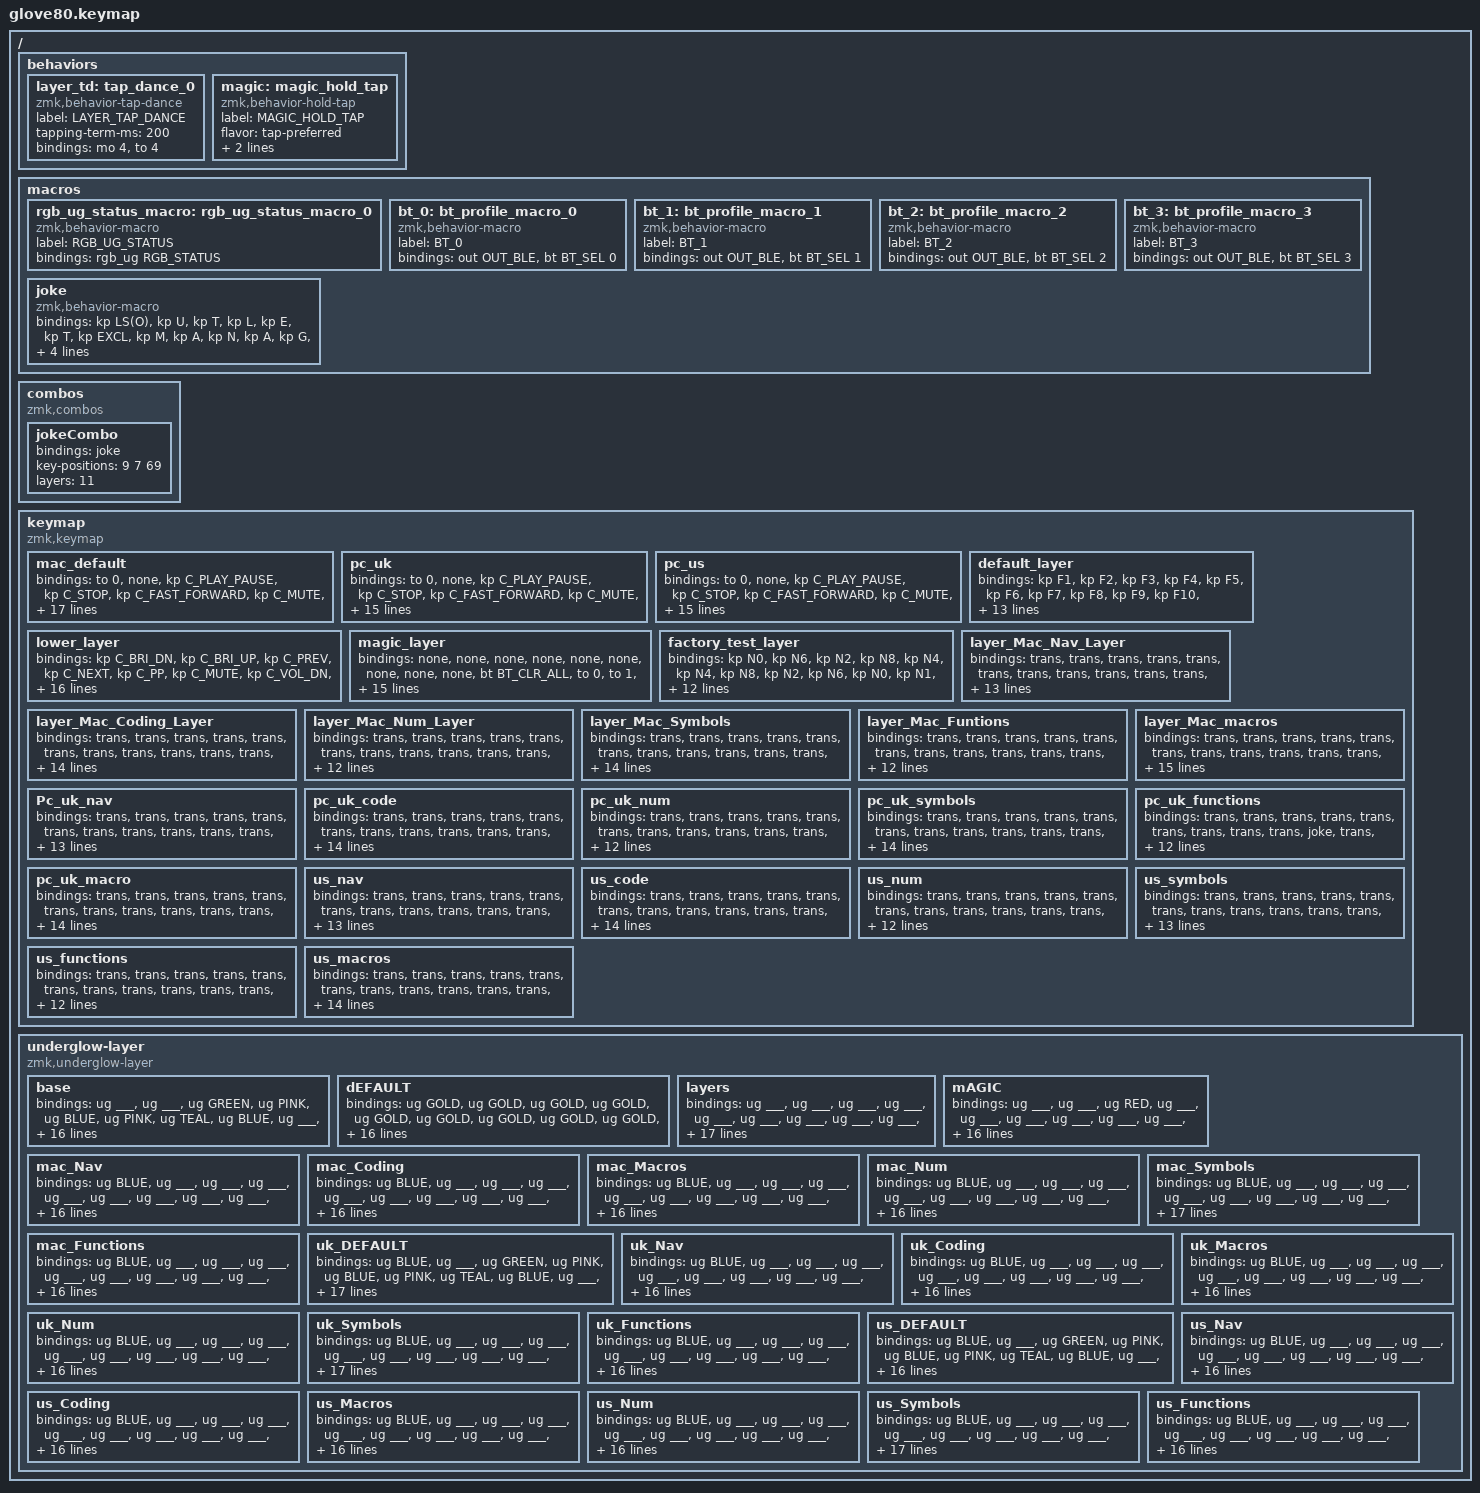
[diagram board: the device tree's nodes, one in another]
/*
 * Copyright (c) 2020 The ZMK Contributors
 *
 * SPDX-License-Identifier: MIT
 */

#include <dt-bindings/zmk/rgb_colors.h>
#include <behaviors.dtsi>
#include <dt-bindings/zmk/bt.h>
#include <dt-bindings/zmk/keys.h>
#include <dt-bindings/zmk/outputs.h>
#include <dt-bindings/zmk/rgb.h>

#define HYPER LC(LS(LG(LALT)))

// layers

#define MAC_DEFAULT 0
#define DEFAULT 3
#define UK_DEFAULT 1
#define US_DEFAULT 2
#define LOWER 4
#define MAGIC 5
#define FACTORY_TEST 6
#define MAC_Nav 7
#define MAC_Coding 8
#define MAC_Num 9
#define MAC_Symbols 10
#define MAC_Functions 11
#define MAC_Macros 12
#define UK_Nav 13
#define UK_Coding 14
#define UK_Num 15
#define UK_Symbols 16
#define UK_Functions 17
#define UK_Macros 18
#define US_Nav 19
#define US_Coding 20
#define US_Num 21
#define US_Symbols 22
#define US_Functions 23
#define US_Macros 24

/ {
    behaviors {
        // For the "layer" key, it'd nice to be able to use it as either a shift or a toggle.
        // Configure it as a tap dance, so the first tap (or hold) is a &mo and the second tap is a &to

        layer_td: tap_dance_0 {
            compatible = "zmk,behavior-tap-dance";
            label = "LAYER_TAP_DANCE";
            #binding-cells = <0>;
            tapping-term-ms = <200>;
            bindings = <&mo 4>, <&to 4>;
        };

        magic: magic_hold_tap {
            compatible = "zmk,behavior-hold-tap";
            label = "MAGIC_HOLD_TAP";
            #binding-cells = <2>;
            flavor = "tap-preferred";
            tapping-term-ms = <200>;
            bindings = <&mo>, <&rgb_ug_status_macro>;
        };
    };

    macros {
        rgb_ug_status_macro: rgb_ug_status_macro_0 {
            label = "RGB_UG_STATUS";
            compatible = "zmk,behavior-macro";
            #binding-cells = <0>;
            bindings = <&rgb_ug RGB_STATUS>;
        };

        bt_0: bt_profile_macro_0 {
            label = "BT_0";
            compatible = "zmk,behavior-macro";
            #binding-cells = <0>;
            bindings = <&out OUT_BLE &bt BT_SEL 0>;
        };

        bt_1: bt_profile_macro_1 {
            label = "BT_1";
            compatible = "zmk,behavior-macro";
            #binding-cells = <0>;
            bindings = <&out OUT_BLE &bt BT_SEL 1>;
        };

        bt_2: bt_profile_macro_2 {
            label = "BT_2";
            compatible = "zmk,behavior-macro";
            #binding-cells = <0>;
            bindings = <&out OUT_BLE &bt BT_SEL 2>;
        };

        bt_3: bt_profile_macro_3 {
            label = "BT_3";
            compatible = "zmk,behavior-macro";
            #binding-cells = <0>;
            bindings = <&out OUT_BLE &bt BT_SEL 3>;
        };

        joke: joke {
            compatible = "zmk,behavior-macro";
            #binding-cells = <0>;
            bindings = <&kp LS(O) &kp U &kp T &kp L &kp E &kp T &kp EXCL &kp M &kp A &kp N &kp A &kp G &kp I &kp N &kp G &kp EXCL &kp W &kp I &kp Z &kp A &kp R &kp D &kp N2 &kp M &kp A &kp K &kp I &kp N &kp G>;
            label = "JOKE";
        };
    };

    combos {
        compatible = "zmk,combos";

        jokeCombo {
            bindings = <&joke>;
            key-positions = <9 7 69>;
            layers = <11>;
        };
    };

    keymap {
        compatible = "zmk,keymap";

        mac_default {
            bindings = <
&to 0       &none               &kp C_PLAY_PAUSE  &kp C_STOP      &kp C_FAST_FORWARD                                                                                                  &kp C_MUTE         &kp C_VOLUME_DOWN  &kp C_VOL_UP     &rgb_ug RGB_ON       &rgb_ug RGB_OFF
&none       &none               &none             &none           &none               &none                                                                                    &none  &none              &none              &none            &none                &none
&none       &kp Q               &kp W             &kp F           &kp P               &kp B                                                                                    &kp J  &kp L              &kp U              &kp Y            &kp LS(SLASH)        &none
&none       &mt LEFT_CONTROL A  &mt LEFT_ALT R    &mt LEFT_WIN S  &mt LEFT_SHIFT T    &kp G                                                                                    &kp M  &mt RIGHT_SHIFT N  &mt RIGHT_WIN E    &mt RIGHT_ALT I  &mt RIGHT_CONTROL O  &none
&none       &kp Z               &kp X             &kp C           &kp D               &kp V  &none        &none       &none       &none          &none        &none            &kp K  &kp H              &kp COMMA          &kp PERIOD       &kp LS(FSLH)         &none
&magic 5 0  &none               &none             &none           &none                      &lt 9 SPACE  &lt 10 TAB  &lt 11 ESC  &lt 12 DELETE  &lt 8 ENTER  &lt 7 BACKSPACE         &none              &none              &none            &none                &magic 5 0
            >;
        };

        pc_uk {
            bindings = <
&to 0       &none           &kp C_PLAY_PAUSE  &kp C_STOP   &kp C_FAST_FORWARD                                                                                                     &kp C_MUTE         &kp C_VOLUME_DOWN  &kp C_VOL_UP     &none              &none
&none       &none           &none             &none        &none               &none                                                                                       &none  &none              &none              &none            &none              &none
&none       &kp Q           &kp W             &kp F        &kp P               &kp B                                                                                       &kp J  &kp L              &kp U              &kp Y            &kp APOS           &none
&none       &mt LEFT_WIN A  &mt LEFT_ALT R    &mt LCTRL S  &mt LEFT_SHIFT T    &kp G                                                                                       &kp M  &mt RIGHT_SHIFT N  &mt RCTRL E        &mt RIGHT_ALT I  &mt RIGHT_WIN O    &none
&none       &kp Z           &kp X             &kp C        &kp D               &kp V  &none         &none       &none       &none          &none         &none             &kp K  &kp H              &kp COMMA          &kp DOT          &kp RA(BACKSLASH)  &none
&magic 5 0  &none           &none             &none        &none                      &lt 15 SPACE  &lt 16 TAB  &lt 17 ESC  &lt 18 DELETE  &lt 14 ENTER  &lt 13 BACKSPACE         &none              &none              &none            &none              &magic 5 0
            >;
        };

        pc_us {
            bindings = <
&to 0       &none           &kp C_PLAY_PAUSE  &kp C_STOP   &kp C_FAST_FORWARD                                                                                                     &kp C_MUTE         &kp C_VOLUME_DOWN  &kp C_VOL_UP     &none            &none
&none       &none           &none             &none        &none               &none                                                                                       &none  &none              &none              &none            &none            &none
&none       &kp Q           &kp W             &kp F        &kp P               &kp B                                                                                       &kp J  &kp L              &kp U              &kp Y            &kp UNDER        &none
&none       &mt LEFT_WIN A  &mt LEFT_ALT R    &mt LCTRL S  &mt LEFT_SHIFT T    &kp G                                                                                       &kp M  &mt RIGHT_SHIFT N  &mt RCTRL E        &mt RIGHT_ALT I  &mt RIGHT_WIN O  &none
&none       &kp Z           &kp X             &kp C        &kp D               &kp V  &none         &none       &none       &none          &none         &none             &kp K  &kp H              &kp COMMA          &kp DOT          &kp LS(FSLH)     &none
&magic 5 0  &none           &none             &none        &none                      &lt 21 SPACE  &lt 22 TAB  &lt 23 ESC  &lt 24 DELETE  &lt 20 ENTER  &lt 19 BACKSPACE         &none              &none              &none            &none            &magic 5 0
            >;
        };

        default_layer {
            // ---------------------------------------------------------------------------------------------------------------------------------
            // |  F1   |  F2 |  F3 |  F4  |  F5  |                                                               |  F6   |  F7   |  F8  |   F9  |  F10 |
            // |  =    |  1  |  2  |  3   |  4   |  5   |                                                 |  6   |   7   |   8   |  9   |   0   |   -  |
            // |  TAB  |  Q  |  W  |  E   |  R   |  T   |                                                 |  Y   |   U   |   I   |  O   |   P   |   \  |
            // |  ESC  |  A  |  S  |  D   |  F   |  G   |                                                 |  H   |   J   |   K   |  L   |   ;   |   '  |
            // |   `   |  Z  |  X  |  C   |  V   |  B   | LSHFT | LCTRL | LOWER | | LGUI  | RCTRL | RSHFT |  N   |   M   |   ,   |  .   |   /   | PGUP |
            // | MAGIC | HOME| END | LEFT | RIGHT|      | BSPC  | DEL   | LALT  | | RALT  | RET   | SPACE |      |  UP   | DOWN  |  [   |   ]   | PGDN |

            bindings = <
&kp F1      &kp F2    &kp F3   &kp F4    &kp F5                                                                                      &kp F6  &kp F7     &kp F8    &kp F9    &kp F10
&kp EQUAL   &kp N1    &kp N2   &kp N3    &kp N4     &kp N5                                                                   &kp N6  &kp N7  &kp N8     &kp N9    &kp N0    &kp MINUS
&kp TAB     &kp Q     &kp W    &kp E     &kp R      &kp T                                                                    &kp Y   &kp U   &kp I      &kp O     &kp P     &kp BSLH
&kp ESC     &kp A     &kp S    &kp D     &kp F      &kp G                                                                    &kp H   &kp J   &kp K      &kp L     &kp SEMI  &kp SQT
&kp GRAVE   &kp Z     &kp X    &kp C     &kp V      &kp B   &kp LSHFT  &kp LCTRL  &layer_td  &kp LGUI  &kp RCTRL  &kp RSHFT  &kp N   &kp M   &kp COMMA  &kp DOT   &kp FSLH  &kp PG_UP
&magic 5 0  &kp HOME  &kp END  &kp LEFT  &kp RIGHT          &kp BSPC   &kp DEL    &kp LALT   &kp RALT  &kp RET    &kp SPACE          &kp UP  &kp DOWN   &kp LBKT  &kp RBKT  &kp PG_DN
            >;
        };

        lower_layer {
            bindings = <
&kp C_BRI_DN  &kp C_BRI_UP  &kp C_PREV  &kp C_NEXT  &kp C_PP                                                                         &kp C_MUTE  &kp C_VOL_DN  &kp C_VOL_UP   &none            &kp PAUSE_BREAK
&trans        &none         &none       &none       &none      &kp HOME                                                   &kp LPAR   &kp KP_NUM  &kp KP_EQUAL  &kp KP_DIVIDE  &kp KP_MULTIPLY  &kp PSCRN
&trans        &none         &none       &kp UP      &none      &kp END                                                    &kp RPAR   &kp KP_N7   &kp KP_N8     &kp KP_N9      &kp KP_MINUS     &kp SLCK
&trans        &none         &kp LEFT    &kp DOWN    &kp RIGHT  &kp PG_UP                                                  &kp PRCNT  &kp KP_N4   &kp KP_N5     &kp KP_N6      &kp KP_PLUS      &none
&trans        &kp K_CMENU   &none       &kp F11     &kp F12    &kp PG_DN  &trans  &trans  &to 3   &trans  &trans  &trans  &kp COMMA  &kp KP_N1   &kp KP_N2     &kp KP_N3      &kp KP_ENTER     &trans
&trans        &kp CAPS      &kp INS     &kp F11     &kp F12               &trans  &trans  &trans  &trans  &trans  &trans             &kp KP_N0   &kp KP_N0     &kp KP_DOT     &kp KP_ENTER     &trans
            >;
        };

        magic_layer {
            bindings = <
&none        &none            &none            &none            &none                                                                                     &none         &none         &none         &none  &bt BT_CLR_ALL
&to 0        &to 1            &to 2            &to 3            &bt_3            &none                                                             &none  &none         &none         &none         &none  &bt BT_CLR
&none        &rgb_ug RGB_SPI  &rgb_ug RGB_SAI  &rgb_ug RGB_HUI  &rgb_ug RGB_BRI  &rgb_ug RGB_TOG                                                   &none  &none         &none         &none         &none  &none
&bootloader  &rgb_ug RGB_SPD  &rgb_ug RGB_SAD  &rgb_ug RGB_HUD  &rgb_ug RGB_BRD  &rgb_ug RGB_EFF                                                   &none  &bt BT_SEL 3  &bt BT_SEL 4  &none         &none  &bootloader
&sys_reset   &none            &none            &none            &none            &none            &bt_2  &bt_3  &none         &none  &none  &none  &none  &bt BT_SEL 0  &bt BT_SEL 1  &bt BT_SEL 2  &none  &sys_reset
&none        &none            &none            &none            &none                             &bt_0  &bt_1  &out OUT_USB  &none  &none  &none         &none         &none         &none         &none  &none
            >;
        };

        factory_test_layer {
            bindings = <
&kp N0  &kp N6  &kp N2  &kp N8  &kp N4                                                                  &kp N4  &kp N8  &kp N2  &kp N6  &kp N0
&kp N1  &kp N7  &kp N3  &kp N9  &kp N5  &kp N0                                                  &kp N0  &kp N5  &kp N9  &kp N3  &kp N7  &kp N1
&kp N2  &kp N8  &kp N4  &kp N0  &kp N6  &kp N1                                                  &kp N1  &kp N6  &kp N0  &kp N4  &kp N8  &kp N2
&kp N3  &kp N9  &kp N5  &kp N1  &kp N7  &kp N2                                                  &kp N2  &kp N7  &kp N1  &kp N5  &kp N9  &kp N3
&kp N4  &kp N0  &kp N6  &kp N2  &kp N8  &kp N3  &kp N4  &kp N5  &kp N6  &kp N6  &kp N5  &kp N4  &kp N3  &kp N8  &kp N2  &kp N6  &kp N0  &kp N4
&kp N5  &kp N1  &kp N7  &kp N3  &kp N9          &kp N7  &kp N8  &kp N9  &kp N9  &kp N8  &kp N7          &kp N9  &kp N3  &kp N7  &kp N1  &kp N5
            >;
        };

        layer_Mac_Nav_Layer {
            bindings = <
&trans  &trans     &trans     &trans     &trans                                                                            &trans  &trans  &trans  &trans  &trans
&trans  &trans     &trans     &trans     &trans     &trans                                                         &trans  &trans  &trans  &trans  &trans  &trans
&trans  &kp PG_UP  &kp HOME   &kp UP     &kp END    &kp PAGE_UP                                                    &trans  &trans  &trans  &trans  &trans  &trans
&trans  &kp F20    &kp LEFT   &kp DOWN   &kp RIGHT  &kp PAGE_DOWN                                                  &trans  &trans  &trans  &trans  &trans  &trans
&trans  &kp LG(Z)  &kp LG(X)  &kp LG(C)  &kp LG(V)  &kp LG(V)      &trans  &trans  &trans  &trans  &trans  &trans  &trans  &trans  &trans  &trans  &trans  &trans
&trans  &trans     &trans     &trans     &trans                    &trans  &trans  &trans  &trans  &trans  &trans          &trans  &trans  &trans  &trans  &trans
            >;
        };

        layer_Mac_Coding_Layer {
            bindings = <
&trans  &trans    &trans    &trans             &trans                                                                                           &trans  &trans  &trans  &trans  &trans
&trans  &trans    &trans    &trans             &trans                 &trans                                                            &trans  &trans  &trans  &trans  &trans  &trans
&trans  &kp AT    &kp SQT   &kp DOUBLE_QUOTES  &kp SEMI               &kp COLON                                                         &trans  &trans  &trans  &trans  &trans  &trans
&trans  &kp FSLH  &kp LBKT  &kp LEFT_BRACE     &kp LEFT_PARENTHESIS   &kp LESS_THAN                                                     &trans  &trans  &trans  &trans  &trans  &trans
&trans  &kp BSLH  &kp RBKT  &kp RIGHT_BRACE    &kp RIGHT_PARENTHESIS  &kp GREATER_THAN  &trans  &trans  &trans  &trans  &trans  &trans  &trans  &trans  &trans  &trans  &trans  &trans
&trans  &trans    &trans    &trans             &trans                                   &trans  &trans  &trans  &trans  &trans  &trans          &trans  &trans  &trans  &trans  &trans
            >;
        };

        layer_Mac_Num_Layer {
            bindings = <
&trans  &trans  &trans  &trans  &trans                                                                               &trans  &trans  &trans  &trans     &trans
&trans  &trans  &trans  &trans  &trans  &trans                                                            &trans     &trans  &trans  &trans  &trans     &trans
&trans  &trans  &trans  &trans  &trans  &trans                                                            &kp PLUS   &kp N7  &kp N8  &kp N9  &kp STAR   &trans
&trans  &trans  &trans  &trans  &trans  &trans                                                            &kp MINUS  &kp N4  &kp N5  &kp N6  &kp FSLH   &trans
&trans  &trans  &trans  &trans  &trans  &trans  &trans  &trans  &trans  &trans         &trans     &trans  &kp DOT    &kp N1  &kp N2  &kp N3  &kp EQUAL  &trans
&trans  &trans  &trans  &trans  &trans          &trans  &trans  &trans  &kp BACKSPACE  &kp ENTER  &kp N0             &trans  &trans  &trans  &trans     &trans
            >;
        };

        layer_Mac_Symbols {
            bindings = <
&trans  &trans  &trans  &trans  &trans                                                                            &trans      &trans       &trans            &trans         &trans
&trans  &trans  &trans  &trans  &trans  &trans                                                         &trans     &trans      &trans       &trans            &trans         &trans
&trans  &trans  &trans  &trans  &trans  &trans                                                         &kp GRAVE  &kp AMPS    &kp ASTRK    &kp HASH          &kp LS(MINUS)  &trans
&trans  &trans  &trans  &trans  &trans  &trans                                                         &kp COLON  &kp DOLLAR  &kp PERCENT  &kp CARET         &kp PLUS       &trans
&trans  &trans  &trans  &trans  &trans  &trans  &trans  &trans  &trans  &trans  &trans  &trans         &kp TILDE  &kp EXCL    &kp AT       &kp RA(NUMBER_3)  &kp PIPE       &trans
&trans  &trans  &trans  &trans  &trans          &trans  &trans  &trans  &trans  &trans  &kp BACKSPACE             &trans      &trans       &trans            &trans         &trans
            >;
        };

        layer_Mac_Funtions {
            bindings = <
&trans  &trans  &trans  &trans  &trans                                                                  &trans  &trans  &trans  &trans   &trans
&trans  &trans  &trans  &trans  &trans  &trans                                                  &trans  &trans  &trans  &trans  &trans   &trans
&trans  &trans  &trans  &trans  &trans  &trans                                                  &none   &kp F7  &kp F8  &kp F9  &kp F12  &trans
&trans  &trans  &trans  &trans  &trans  &trans                                                  &none   &kp F4  &kp F5  &kp F6  &kp F11  &trans
&trans  &trans  &trans  &trans  &trans  &trans  &trans  &trans  &trans  &trans  &trans  &trans  &none   &kp F1  &kp F2  &kp F3  &kp F10  &trans
&trans  &trans  &trans  &trans  &trans          &trans  &trans  &trans  &trans  &trans  &trans          &trans  &trans  &trans  &trans   &trans
            >;
        };

        layer_Mac_macros {
            bindings = <
&trans  &trans                &trans                  &trans             &trans                                                                                     &trans  &trans  &trans  &trans  &trans
&trans  &trans                &trans                  &trans             &trans                     &trans                                                  &trans  &trans  &trans  &trans  &trans  &trans
&trans  &kp LC(LS(O))         &kp LA(LC(LEFT_ARROW))  &kp LA(LC(RET))    &kp LA(LC(RIGHT))          &trans                                                  &trans  &trans  &trans  &trans  &trans  &trans
&trans  &kp LC(LS(C))         &kp LG(SPACE)           &kp LG(LA(C))      &kp LS(LA(LC(LG(SPACE))))  &trans                                                  &trans  &trans  &trans  &trans  &trans  &trans
&trans  &kp LA(SINGLE_QUOTE)  &kp LC(PERIOD)          &kp LA(BACKSLASH)  &kp LG(T)                  &trans  &trans  &trans  &trans  &trans  &trans  &trans  &trans  &trans  &trans  &trans  &trans  &trans
&trans  &trans                &trans                  &trans             &trans                             &trans  &trans  &trans  &trans  &trans  &trans          &trans  &trans  &trans  &trans  &trans
            >;
        };

        Pc_uk_nav {
            bindings = <
&trans  &trans     &trans     &trans     &trans                                                                            &trans  &trans  &trans  &trans  &trans
&trans  &trans     &trans     &trans     &trans     &trans                                                         &trans  &trans  &trans  &trans  &trans  &trans
&trans  &kp PG_UP  &kp HOME   &kp UP     &kp END    &kp PAGE_UP                                                    &trans  &trans  &trans  &trans  &trans  &trans
&trans  &kp PG_DN  &kp LEFT   &kp DOWN   &kp RIGHT  &kp PAGE_DOWN                                                  &trans  &trans  &trans  &trans  &trans  &trans
&trans  &kp LC(Z)  &kp LC(X)  &kp LC(C)  &kp LC(V)  &kp LC(V)      &trans  &trans  &trans  &trans  &trans  &trans  &trans  &trans  &trans  &trans  &trans  &trans
&trans  &trans     &trans     &trans     &trans                    &trans  &trans  &trans  &trans  &trans  &trans          &trans  &trans  &trans  &trans  &trans
            >;
        };

        pc_uk_code {
            bindings = <
&trans  &trans             &trans    &trans           &trans                                                                                           &trans  &trans  &trans  &trans  &trans
&trans  &trans             &trans    &trans           &trans                 &trans                                                            &trans  &trans  &trans  &trans  &trans  &trans
&trans  &kp DOUBLE_QUOTES  &kp SQT   &kp AT           &kp SEMI               &kp COLON                                                         &trans  &trans  &trans  &trans  &trans  &trans
&trans  &kp FSLH           &kp LBKT  &kp LEFT_BRACE   &kp LEFT_PARENTHESIS   &kp LESS_THAN                                                     &trans  &trans  &trans  &trans  &trans  &trans
&trans  &kp BSLH           &kp RBKT  &kp RIGHT_BRACE  &kp RIGHT_PARENTHESIS  &kp GREATER_THAN  &trans  &trans  &trans  &trans  &trans  &trans  &trans  &trans  &trans  &trans  &trans  &trans
&trans  &trans             &trans    &trans           &trans                                   &trans  &trans  &trans  &trans  &trans  &trans          &trans  &trans  &trans  &trans  &trans
            >;
        };

        pc_uk_num {
            bindings = <
&trans  &trans  &trans  &trans  &trans                                                                               &trans  &trans  &trans  &trans     &trans
&trans  &trans  &trans  &trans  &trans  &trans                                                            &trans     &trans  &trans  &trans  &trans     &trans
&trans  &trans  &trans  &trans  &trans  &trans                                                            &kp PLUS   &kp N7  &kp N8  &kp N9  &kp STAR   &trans
&trans  &trans  &trans  &trans  &trans  &trans                                                            &kp MINUS  &kp N4  &kp N5  &kp N6  &kp FSLH   &trans
&trans  &trans  &trans  &trans  &trans  &trans  &trans  &trans  &trans  &trans         &trans     &trans  &kp DOT    &kp N1  &kp N2  &kp N3  &kp EQUAL  &trans
&trans  &trans  &trans  &trans  &trans          &trans  &trans  &trans  &kp BACKSPACE  &kp ENTER  &kp N0             &trans  &trans  &trans  &trans     &trans
            >;
        };

        pc_uk_symbols {
            bindings = <
&trans  &trans  &trans  &trans  &trans                                                                            &trans      &trans             &trans         &trans             &trans
&trans  &trans  &trans  &trans  &trans  &trans                                                         &trans     &trans      &trans             &trans         &trans             &trans
&trans  &trans  &trans  &trans  &trans  &trans                                                         &kp GRAVE  &kp AMPS    &kp ASTRK          &kp HASH       &kp UNDER          &trans
&trans  &trans  &trans  &trans  &trans  &trans                                                         &kp TILDE  &kp DOLLAR  &kp PERCENT        &kp CARET      &kp PLUS           &trans
&trans  &trans  &trans  &trans  &trans  &trans  &trans  &trans  &trans  &trans  &trans  &trans         &kp PIPE   &kp EXCL    &kp DOUBLE_QUOTES  &kp BACKSLASH  &kp LS(BACKSLASH)  &trans
&trans  &trans  &trans  &trans  &trans          &trans  &trans  &trans  &trans  &trans  &kp BACKSPACE             &trans      &trans             &trans         &trans             &trans
            >;
        };

        pc_uk_functions {
            bindings = <
&trans  &trans  &trans  &trans  &trans                                                                  &trans  &trans  &trans  &trans   &joke
&trans  &trans  &trans  &trans  &trans  &trans                                                  &trans  &trans  &trans  &trans  &trans   &trans
&trans  &trans  &trans  &trans  &trans  &trans                                                  &none   &kp F7  &kp F8  &kp F9  &kp F12  &trans
&trans  &trans  &trans  &trans  &trans  &trans                                                  &none   &kp F4  &kp F5  &kp F6  &kp F11  &trans
&trans  &trans  &trans  &trans  &trans  &trans  &trans  &trans  &trans  &trans  &trans  &trans  &none   &kp F1  &kp F2  &kp F3  &kp F10  &trans
&trans  &trans  &trans  &trans  &trans          &trans  &trans  &trans  &trans  &trans  &trans          &trans  &trans  &trans  &trans   &trans
            >;
        };

        pc_uk_macro {
            bindings = <
&trans  &trans                &trans          &trans             &trans                                                                                 &trans  &trans  &trans  &trans  &trans
&trans  &trans                &trans          &trans             &trans                 &trans                                                  &trans  &trans  &trans  &trans  &trans  &trans
&trans  &none                 &trans          &trans             &trans                 &trans                                                  &trans  &trans  &trans  &trans  &trans  &trans
&trans  &kp PRINTSCREEN       &kp LG(SPACE)   &kp LA(LC(LS(C)))  &kp LS(LA(LC(SPACE)))  &trans                                                  &trans  &trans  &trans  &trans  &trans  &trans
&trans  &kp LA(SINGLE_QUOTE)  &kp LC(PERIOD)  &kp LA(BACKSLASH)  &kp LG(T)              &trans  &trans  &trans  &trans  &trans  &trans  &trans  &trans  &trans  &trans  &trans  &trans  &trans
&trans  &trans                &trans          &trans             &trans                         &trans  &trans  &trans  &trans  &trans  &trans          &trans  &trans  &trans  &trans  &trans
            >;
        };

        us_nav {
            bindings = <
&trans  &trans     &trans     &trans     &trans                                                                            &trans  &trans  &trans  &trans  &trans
&trans  &trans     &trans     &trans     &trans     &trans                                                         &trans  &trans  &trans  &trans  &trans  &trans
&trans  &kp PG_UP  &kp HOME   &kp UP     &kp END    &kp PAGE_UP                                                    &trans  &trans  &trans  &trans  &trans  &trans
&trans  &kp PG_DN  &kp LEFT   &kp DOWN   &kp RIGHT  &kp PAGE_DOWN                                                  &trans  &trans  &trans  &trans  &trans  &trans
&trans  &kp LC(Z)  &kp LC(X)  &kp LC(C)  &kp LC(V)  &kp LC(V)      &trans  &trans  &trans  &trans  &trans  &trans  &trans  &trans  &trans  &trans  &trans  &trans
&trans  &trans     &trans     &trans     &trans                    &trans  &trans  &trans  &trans  &trans  &trans          &trans  &trans  &trans  &trans  &trans
            >;
        };

        us_code {
            bindings = <
&trans  &trans    &trans    &trans             &trans                                                                                           &trans  &trans  &trans  &trans  &trans
&trans  &trans    &trans    &trans             &trans                 &trans                                                            &trans  &trans  &trans  &trans  &trans  &trans
&trans  &kp AT    &kp SQT   &kp DOUBLE_QUOTES  &kp SEMI               &kp COLON                                                         &trans  &trans  &trans  &trans  &trans  &trans
&trans  &kp FSLH  &kp LBKT  &kp LEFT_BRACE     &kp LEFT_PARENTHESIS   &kp LESS_THAN                                                     &trans  &trans  &trans  &trans  &trans  &trans
&trans  &kp BSLH  &kp RBKT  &kp RIGHT_BRACE    &kp RIGHT_PARENTHESIS  &kp GREATER_THAN  &trans  &trans  &trans  &trans  &trans  &trans  &trans  &trans  &trans  &trans  &trans  &trans
&trans  &trans    &trans    &trans             &trans                                   &trans  &trans  &trans  &trans  &trans  &trans          &trans  &trans  &trans  &trans  &trans
            >;
        };

        us_num {
            bindings = <
&trans  &trans  &trans  &trans  &trans                                                                               &trans  &trans  &trans  &trans     &trans
&trans  &trans  &trans  &trans  &trans  &trans                                                            &trans     &trans  &trans  &trans  &trans     &trans
&trans  &trans  &trans  &trans  &trans  &trans                                                            &kp PLUS   &kp N7  &kp N8  &kp N9  &kp STAR   &trans
&trans  &trans  &trans  &trans  &trans  &trans                                                            &kp MINUS  &kp N4  &kp N5  &kp N6  &kp FSLH   &trans
&trans  &trans  &trans  &trans  &trans  &trans  &trans  &trans  &trans  &trans         &trans     &trans  &kp DOT    &kp N1  &kp N2  &kp N3  &kp EQUAL  &trans
&trans  &trans  &trans  &trans  &trans          &trans  &trans  &trans  &kp BACKSPACE  &kp ENTER  &kp N0             &trans  &trans  &trans  &trans     &trans
            >;
        };

        us_symbols {
            bindings = <
&trans  &trans  &trans  &trans  &trans                                                                     &trans      &trans       &trans     &trans     &trans
&trans  &trans  &trans  &trans  &trans  &trans                                                  &trans     &trans      &trans       &trans     &trans     &trans
&trans  &trans  &trans  &trans  &trans  &trans                                                  &kp GRAVE  &kp AMPS    &kp ASTRK    &kp HASH   &kp UNDER  &trans
&trans  &trans  &trans  &trans  &trans  &trans                                                  &kp COLON  &kp DOLLAR  &kp PERCENT  &kp CARET  &kp PLUS   &trans
&trans  &trans  &trans  &trans  &trans  &trans  &trans  &trans  &trans  &trans  &trans  &trans  &kp TILDE  &kp EXCL    &kp AT       &kp HASH   &kp PIPE   &trans
&trans  &trans  &trans  &trans  &trans          &trans  &trans  &trans  &trans  &trans  &trans             &trans      &trans       &trans     &trans     &trans
            >;
        };

        us_functions {
            bindings = <
&trans  &trans  &trans  &trans  &trans                                                                  &trans  &trans  &trans  &trans   &trans
&trans  &trans  &trans  &trans  &trans  &trans                                                  &trans  &trans  &trans  &trans  &trans   &trans
&trans  &trans  &trans  &trans  &trans  &trans                                                  &none   &kp F7  &kp F8  &kp F9  &kp F12  &trans
&trans  &trans  &trans  &trans  &trans  &trans                                                  &none   &kp F4  &kp F5  &kp F6  &kp F11  &trans
&trans  &trans  &trans  &trans  &trans  &trans  &trans  &trans  &trans  &trans  &trans  &trans  &none   &kp F1  &kp F2  &kp F3  &kp F10  &trans
&trans  &trans  &trans  &trans  &trans          &trans  &trans  &trans  &trans  &trans  &trans          &trans  &trans  &trans  &trans   &trans
            >;
        };

        us_macros {
            bindings = <
&trans  &trans                &trans          &trans             &trans                                                                                 &trans  &trans  &trans  &trans  &trans
&trans  &trans                &trans          &trans             &trans                 &trans                                                  &trans  &trans  &trans  &trans  &trans  &trans
&trans  &none                 &trans          &trans             &trans                 &trans                                                  &trans  &trans  &trans  &trans  &trans  &trans
&trans  &kp PRINTSCREEN       &kp LG(SPACE)   &kp LA(LC(LS(C)))  &kp LS(LA(LC(SPACE)))  &trans                                                  &trans  &trans  &trans  &trans  &trans  &trans
&trans  &kp LA(SINGLE_QUOTE)  &kp LC(PERIOD)  &kp LA(BACKSLASH)  &kp LG(T)              &trans  &trans  &trans  &trans  &trans  &trans  &trans  &trans  &trans  &trans  &trans  &trans  &trans
&trans  &trans                &trans          &trans             &trans                         &trans  &trans  &trans  &trans  &trans  &trans          &trans  &trans  &trans  &trans  &trans
            >;
        };
    };

    underglow-layer {
        compatible = "zmk,underglow-layer";

        base {
            bindings = <
                &ug ___   &ug ___     &ug GREEN   &ug PINK    &ug BLUE                                                                                                     &ug PINK    &ug TEAL    &ug BLUE    &ug ___     &ug WHITE
                &ug BLUE   &ug ___    &ug ___     &ug ___     &ug ___   &ug ___                                                                                &ug ___     &ug ___     &ug ___     &ug ___     &ug ___     &ug ___
                &ug ___   &ug BLUE    &ug BLUE    &ug BLUE    &ug BLUE    &ug BLUE                                                                             &ug BLUE    &ug BLUE    &ug BLUE    &ug BLUE    &ug GREEN   &ug ___
                &ug ___   &ug BLUE    &ug BLUE    &ug BLUE    &ug BLUE    &ug BLUE                                                                             &ug BLUE    &ug BLUE    &ug BLUE    &ug BLUE    &ug BLUE    &ug ___
                &ug ___   &ug BLUE    &ug BLUE    &ug BLUE    &ug BLUE    &ug BLUE    &ug ___     &ug ___     &ug ___      &ug ___     &ug ___     &ug ___     &ug BLUE    &ug BLUE    &ug GREEN   &ug GREEN   &ug GREEN   &ug ___
                &ug GOLD  &ug ___     &ug ___     &ug ___     &ug ___                 &ug WHITE   &ug YELLOW  &ug PINK     &ug PINK    &ug GREEN   &ug RED                 &ug ___     &ug ___     &ug ___     &ug ___     &ug GOLD
            >;

            layer-id = <MAC_DEFAULT>;
        };

        dEFAULT {
            bindings = <
                &ug GOLD   &ug GOLD     &ug GOLD     &ug GOLD     &ug GOLD                                                                                                  &ug GOLD    &ug GOLD    &ug GOLD    &ug GOLD   &ug GOLD
                &ug GOLD   &ug GOLD     &ug GOLD     &ug GOLD     &ug GOLD   &ug GOLD                                                                            &ug GOLD   &ug GOLD    &ug GOLD    &ug GOLD    &ug GOLD   &ug GOLD
                &ug GOLD   &ug GOLD     &ug GOLD     &ug GOLD     &ug GOLD   &ug GOLD                                                                            &ug GOLD   &ug GOLD    &ug GOLD    &ug GOLD    &ug GOLD   &ug GOLD
                &ug GOLD   &ug GOLD     &ug GOLD     &ug GOLD     &ug GOLD   &ug GOLD                                                                            &ug GOLD   &ug GOLD    &ug GOLD    &ug GOLD    &ug GOLD   &ug GOLD
                &ug GOLD   &ug GOLD     &ug GOLD     &ug GOLD     &ug GOLD   &ug GOLD      &ug GOLD   &ug GOLD   &ug GOLD    &ug GOLD    &ug GOLD   &ug GOLD     &ug GOLD   &ug GOLD    &ug GOLD    &ug GOLD    &ug GOLD   &ug GOLD
                &ug GOLD   &ug GOLD     &ug GOLD     &ug GOLD     &ug GOLD                 &ug GOLD   &ug GOLD   &ug GOLD    &ug RED     &ug GOLD   &ug GOLD                &ug GOLD    &ug GOLD    &ug GOLD    &ug GOLD   &ug GOLD
            >;

            layer-id = <DEFAULT>;
        };

        layers {
            bindings = <
                &ug ___   &ug ___     &ug ___     &ug ___     &ug ___                                                                                                      &ug ___     &ug ___     &ug ___     &ug ___     &ug ___
                &ug ___   &ug ___     &ug ___     &ug ___     &ug ___   &ug ___                                                                                &ug ___     &ug ___     &ug ___     &ug ___     &ug ___     &ug ___
                &ug ___   &ug WHITE   &ug WHITE   &ug WHITE   &ug WHITE   &ug WHITE                                                                            &ug GREEN   &ug BLUE    &ug BLUE    &ug BLUE    &ug GREEN   &ug ___
                &ug ___   &ug WHITE   &ug WHITE   &ug WHITE   &ug WHITE   &ug WHITE                                                                            &ug GREEN   &ug BLUE    &ug BLUE    &ug BLUE    &ug GREEN   &ug ___
                &ug ___   &ug WHITE   &ug WHITE   &ug WHITE   &ug WHITE   &ug WHITE   &ug ___     &ug ___     &ug ___      &ug ___     &ug ___     &ug ___     &ug GREEN   &ug BLUE    &ug BLUE    &ug BLUE    &ug WHITE   &ug ___
                &ug GOLD  &ug ___     &ug ___     &ug ___     &ug ___                 &ug WHITE   &ug WHITE   &ug WHITE    &ug RED     &ug WHITE   &ug BLUE                &ug ___     &ug ___     &ug ___     &ug ___     &ug GOLD
            >;

            layer-id = <LOWER>;
        };

        mAGIC {
            bindings = <
                &ug ___    &ug ___     &ug RED     &ug ___      &ug ___                                                                                                            &ug ___     &ug ___     &ug ___     &ug ___     &ug RED
                &ug BLUE   &ug GREEN   &ug RED     &ug GOLD     &ug ___       &ug ___                                                                                  &ug ___     &ug ___     &ug ___     &ug ___     &ug ___     &ug PINK
                &ug ___    &ug GREEN   &ug ORANGE  &ug GOLD     &ug WHITE     &ug GREEN                                                                                &ug ___     &ug ___     &ug ___     &ug ___     &ug ___     &ug ___
                &ug RED    &ug GREEN   &ug ORANGE  &ug GOLD     &ug WHITE     &ug ___                                                                                  &ug ___     &ug ___     &ug ___     &ug ___     &ug ___     &ug RED
                &ug PURPLE &ug ___     &ug ___     &ug ___      &ug PURPLE    &ug ___     &ug BLUE     &ug BLUE    &ug ___      &ug ___     &ug ___     &ug ___        &ug ___     &ug ___     &ug ___     &ug ___     &ug ___     &ug PURPLE
                &ug ___    &ug ___     &ug ___     &ug ___      &ug ___                   &ug BLUE     &ug BLUE    &ug TEAL     &ug ___     &ug ___     &ug ___                    &ug ___     &ug ___     &ug ___     &ug ___     &ug ___
            >;

            layer-id = <MAGIC>;
        };

        mac_Nav {
            bindings = <
                &ug BLUE  &ug ___     &ug ___     &ug ___     &ug ___                                                                                                       &ug ___     &ug ___     &ug ___     &ug ___     &ug ___
                &ug ___   &ug ___     &ug ___     &ug ___     &ug ___     &ug ___                                                                                 &ug ___   &ug ___     &ug ___     &ug ___     &ug ___     &ug ___
                &ug ___   &ug GREEN   &ug PURPLE  &ug BLUE    &ug PURPLE  &ug GREEN                                                                               &ug ___   &ug ___     &ug ___     &ug ___     &ug ___     &ug ___
                &ug ___   &ug GREEN   &ug BLUE    &ug BLUE    &ug BLUE    &ug GREEN                                                                               &ug ___   &ug BLUE    &ug BLUE    &ug BLUE    &ug BLUE    &ug ___
                &ug ___   &ug TEAL    &ug TEAL    &ug TEAL    &ug TEAL    &ug TEAL    &ug ___     &ug ___     &ug ___      &ug ___     &ug ___     &ug ___        &ug ___   &ug ___     &ug ___     &ug ___     &ug ___     &ug ___
                &ug ___   &ug ___     &ug ___     &ug ___     &ug ___                 &ug WHITE   &ug YELLOW   &ug PINK    &ug ___     &ug ___   &ug ___                    &ug ___     &ug ___     &ug ___     &ug ___     &ug ___
            >;

            layer-id = <MAC_Nav>;
        };

        mac_Coding {
            bindings = <
                &ug BLUE  &ug ___     &ug ___     &ug ___      &ug ___                                                                                                        &ug ___     &ug ___     &ug ___     &ug ___     &ug ___
                &ug ___   &ug ___     &ug ___     &ug ___      &ug ___     &ug ___                                                                                &ug ___     &ug ___     &ug ___     &ug ___     &ug ___     &ug ___
                &ug ___   &ug TEAL    &ug TEAL    &ug TEAL     &ug TEAL    &ug TEAL                                                                               &ug ___     &ug ___     &ug ___     &ug ___     &ug ___     &ug ___
                &ug ___   &ug GREEN   &ug BLUE    &ug PURPLE   &ug YELLOW  &ug RED                                                                                &ug ___     &ug BLUE    &ug BLUE    &ug BLUE    &ug BLUE    &ug ___
                &ug ___   &ug GREEN   &ug BLUE    &ug PURPLE   &ug YELLOW  &ug RED     &ug ___     &ug ___     &ug ___      &ug ___     &ug ___     &ug ___       &ug ___     &ug ___     &ug ___     &ug ___     &ug ___     &ug ___
                &ug ___   &ug ___     &ug ___     &ug ___      &ug ___                 &ug WHITE   &ug YELLOW  &ug PINK     &ug ___     &ug ___    &ug ___                    &ug ___     &ug ___     &ug ___     &ug ___     &ug ___
            >;

            layer-id = <MAC_Coding>;
        };

        mac_Macros {
            bindings = <
                &ug BLUE  &ug ___     &ug ___     &ug ___      &ug ___                                                                                                        &ug ___     &ug ___     &ug ___     &ug ___     &ug ___
                &ug ___   &ug ___     &ug ___     &ug ___      &ug ___     &ug ___                                                                                &ug ___     &ug ___     &ug ___     &ug ___     &ug ___     &ug ___
                &ug ___   &ug GREEN   &ug ___     &ug ___      &ug ___     &ug ___                                                                                &ug ___     &ug ___     &ug ___     &ug ___     &ug ___     &ug ___
                &ug ___   &ug GREEN   &ug BLUE    &ug TEAL     &ug BLUE    &ug ___                                                                                &ug ___     &ug BLUE    &ug BLUE    &ug BLUE    &ug BLUE    &ug ___
                &ug ___   &ug PURPLE  &ug PURPLE  &ug PURPLE   &ug PURPLE  &ug ___     &ug ___     &ug ___     &ug ___      &ug ___     &ug ___     &ug ___       &ug ___     &ug ___     &ug ___     &ug ___     &ug ___     &ug ___
                &ug ___   &ug ___     &ug ___     &ug ___      &ug ___                 &ug WHITE   &ug YELLOW  &ug PINK     &ug ___     &ug ___     &ug ___                   &ug ___     &ug ___     &ug ___     &ug ___     &ug ___
            >;

            layer-id = <MAC_Macros>;
        };

        mac_Num {
            bindings = <
                &ug BLUE  &ug ___     &ug ___     &ug ___      &ug ___                                                                                                        &ug ___     &ug ___     &ug ___     &ug ___     &ug ___
                &ug ___   &ug ___     &ug ___     &ug ___      &ug ___     &ug ___                                                                                &ug ___     &ug ___     &ug ___     &ug ___     &ug ___     &ug ___
                &ug ___   &ug ___     &ug ___     &ug ___      &ug ___     &ug ___                                                                                &ug GREEN   &ug BLUE    &ug BLUE    &ug BLUE    &ug GREEN   &ug ___
                &ug ___   &ug BLUE    &ug BLUE    &ug BLUE     &ug BLUE    &ug ___                                                                                &ug GREEN   &ug BLUE    &ug BLUE    &ug BLUE    &ug GREEN   &ug ___
                &ug ___   &ug ___     &ug ___     &ug ___      &ug ___     &ug ___     &ug ___     &ug ___     &ug ___      &ug ___     &ug ___     &ug ___       &ug TEAL    &ug BLUE    &ug BLUE    &ug BLUE    &ug TEAL    &ug ___
                &ug ___   &ug ___     &ug ___     &ug ___      &ug ___                 &ug ___     &ug ___     &ug ___      &ug RED     &ug GREEN   &ug BLUE                  &ug ___     &ug ___     &ug ___     &ug ___     &ug ___
            >;

            layer-id = <MAC_Num>;
        };

        mac_Symbols {
            bindings = <
                &ug BLUE  &ug ___     &ug ___     &ug ___      &ug ___                                                                                                        &ug ___     &ug ___     &ug ___     &ug ___     &ug ___
                &ug ___   &ug ___     &ug ___     &ug ___      &ug ___     &ug ___                                                                                &ug ___     &ug ___     &ug ___     &ug ___     &ug ___     &ug ___
                &ug ___   &ug ___     &ug ___     &ug ___      &ug ___     &ug ___                                                                                &ug GREEN   &ug GREEN   &ug GREEN   &ug GREEN   &ug GREEN   &ug ___
                &ug ___   &ug BLUE    &ug BLUE    &ug BLUE     &ug BLUE    &ug ___                                                                                &ug GREEN   &ug GREEN   &ug GREEN   &ug GREEN   &ug GREEN   &ug ___
                &ug ___   &ug ___     &ug ___     &ug ___      &ug ___     &ug ___     &ug ___     &ug ___     &ug ___      &ug ___     &ug ___     &ug ___       &ug GREEN   &ug GREEN   &ug GREEN   &ug GREEN   &ug GREEN    &ug ___
                &ug ___   &ug ___     &ug ___     &ug ___      &ug ___                 &ug ___     &ug ___     &ug ___      &ug PINK    &ug GREEN   &ug RED                   &ug ___     &ug ___     &ug ___     &ug ___     &ug ___
            >;

            layer-id = <MAC_Symbols>;
        };

        mac_Functions {
            bindings = <
                &ug BLUE  &ug ___     &ug ___     &ug ___      &ug ___                                                                                                        &ug ___     &ug ___     &ug ___     &ug ___     &ug ___
                &ug ___   &ug ___     &ug ___     &ug ___      &ug ___     &ug ___                                                                                &ug ___     &ug ___     &ug ___     &ug ___     &ug ___     &ug ___
                &ug ___   &ug ___     &ug ___     &ug ___      &ug ___     &ug ___                                                                                &ug ___     &ug BLUE    &ug BLUE    &ug BLUE    &ug TEAL    &ug ___
                &ug ___   &ug BLUE    &ug BLUE    &ug BLUE     &ug BLUE    &ug ___                                                                                &ug ___     &ug BLUE    &ug BLUE    &ug BLUE    &ug TEAL    &ug ___
                &ug ___   &ug ___     &ug ___     &ug ___      &ug ___     &ug ___     &ug ___     &ug ___     &ug ___      &ug ___     &ug ___     &ug ___       &ug ___     &ug BLUE    &ug BLUE    &ug BLUE    &ug TEAL    &ug ___
                &ug ___   &ug ___     &ug ___     &ug ___      &ug ___                 &ug ___     &ug ___     &ug ___      &ug PINK    &ug GREEN   &ug RED                   &ug ___     &ug ___     &ug ___     &ug ___     &ug ___
            >;

            layer-id = <MAC_Functions>;
        };

        uk_DEFAULT {
            bindings = <
                &ug BLUE  &ug ___     &ug GREEN   &ug PINK    &ug BLUE                                                                                                     &ug PINK    &ug TEAL    &ug BLUE    &ug ___     &ug ___
                &ug ___   &ug GREEN    &ug ___   &ug ___     &ug ___   &ug ___                                                                                &ug ___     &ug ___     &ug ___     &ug ___     &ug ___     &ug ___
                &ug ___   &ug GREEN   &ug GREEN   &ug GREEN   &ug GREEN   &ug GREEN                                                                            &ug GREEN   &ug GREEN   &ug GREEN   &ug GREEN   &ug GREEN   &ug ___
                &ug ___   &ug GREEN   &ug GREEN   &ug GREEN   &ug GREEN   &ug GREEN                                                                            &ug GREEN   &ug GREEN   &ug GREEN   &ug GREEN   &ug GREEN   &ug ___
                &ug ___   &ug GREEN   &ug GREEN   &ug GREEN   &ug GREEN   &ug GREEN   &ug ___     &ug ___     &ug ___      &ug ___     &ug ___     &ug ___     &ug GREEN   &ug GREEN   &ug GREEN   &ug GREEN   &ug GREEN   &ug ___
                &ug GOLD  &ug ___     &ug ___     &ug ___     &ug ___                 &ug WHITE   &ug YELLOW  &ug PINK     &ug PINK    &ug GREEN   &ug RED                 &ug ___     &ug ___     &ug ___     &ug ___     &ug GOLD
            >;

            layer-id = <UK_DEFAULT>;
        };

        uk_Nav {
            bindings = <
                &ug BLUE  &ug ___     &ug ___     &ug ___     &ug ___                                                                                                       &ug ___     &ug ___     &ug ___     &ug ___     &ug ___
                &ug ___   &ug ___     &ug ___     &ug ___     &ug ___     &ug ___                                                                                 &ug ___   &ug ___     &ug ___     &ug ___     &ug ___     &ug ___
                &ug ___   &ug GREEN   &ug PURPLE  &ug BLUE    &ug PURPLE  &ug GREEN                                                                               &ug ___   &ug ___     &ug ___     &ug ___     &ug ___     &ug ___
                &ug ___   &ug GREEN   &ug BLUE    &ug BLUE    &ug BLUE    &ug GREEN                                                                               &ug ___   &ug BLUE    &ug BLUE    &ug BLUE    &ug BLUE    &ug ___
                &ug ___   &ug TEAL    &ug TEAL    &ug TEAL    &ug TEAL    &ug TEAL    &ug ___     &ug ___     &ug ___      &ug ___     &ug ___     &ug ___        &ug ___   &ug ___     &ug ___     &ug ___     &ug ___     &ug ___
                &ug ___   &ug ___     &ug ___     &ug ___     &ug ___                 &ug WHITE   &ug YELLOW   &ug PINK    &ug ___     &ug ___   &ug ___                    &ug ___     &ug ___     &ug ___     &ug ___     &ug ___
            >;

            layer-id = <UK_Nav>;
        };

        uk_Coding {
            bindings = <
                &ug BLUE  &ug ___     &ug ___     &ug ___      &ug ___                                                                                                        &ug ___     &ug ___     &ug ___     &ug ___     &ug ___
                &ug ___   &ug ___     &ug ___     &ug ___      &ug ___     &ug ___                                                                                &ug ___     &ug ___     &ug ___     &ug ___     &ug ___     &ug ___
                &ug ___   &ug TEAL    &ug TEAL    &ug TEAL     &ug TEAL    &ug TEAL                                                                               &ug ___     &ug ___     &ug ___     &ug ___     &ug ___     &ug ___
                &ug ___   &ug GREEN   &ug BLUE    &ug PURPLE   &ug YELLOW  &ug RED                                                                                &ug ___     &ug BLUE    &ug BLUE    &ug BLUE    &ug BLUE    &ug ___
                &ug ___   &ug GREEN   &ug BLUE    &ug PURPLE   &ug YELLOW  &ug RED     &ug ___     &ug ___     &ug ___      &ug ___     &ug ___     &ug ___       &ug ___     &ug ___     &ug ___     &ug ___     &ug ___     &ug ___
                &ug ___   &ug ___     &ug ___     &ug ___      &ug ___                 &ug WHITE   &ug YELLOW  &ug PINK     &ug ___     &ug ___    &ug ___                    &ug ___     &ug ___     &ug ___     &ug ___     &ug ___
            >;

            layer-id = <UK_Coding>;
        };

        uk_Macros {
            bindings = <
                &ug BLUE  &ug ___     &ug ___     &ug ___      &ug ___                                                                                                        &ug ___     &ug ___     &ug ___     &ug ___     &ug ___
                &ug ___   &ug ___     &ug ___     &ug ___      &ug ___     &ug ___                                                                                &ug ___     &ug ___     &ug ___     &ug ___     &ug ___     &ug ___
                &ug ___   &ug GREEN   &ug ___     &ug ___      &ug ___     &ug ___                                                                                &ug ___     &ug ___     &ug ___     &ug ___     &ug ___     &ug ___
                &ug ___   &ug GREEN   &ug BLUE    &ug TEAL     &ug BLUE    &ug ___                                                                                &ug ___     &ug BLUE    &ug BLUE    &ug BLUE    &ug BLUE    &ug ___
                &ug ___   &ug PURPLE  &ug PURPLE  &ug PURPLE   &ug PURPLE  &ug ___     &ug ___     &ug ___     &ug ___      &ug ___     &ug ___     &ug ___       &ug ___     &ug ___     &ug ___     &ug ___     &ug ___     &ug ___
                &ug ___   &ug ___     &ug ___     &ug ___      &ug ___                 &ug WHITE   &ug YELLOW  &ug PINK     &ug ___     &ug ___     &ug ___                   &ug ___     &ug ___     &ug ___     &ug ___     &ug ___
            >;

            layer-id = <UK_Macros>;
        };

        uk_Num {
            bindings = <
                &ug BLUE  &ug ___     &ug ___     &ug ___      &ug ___                                                                                                        &ug ___     &ug ___     &ug ___     &ug ___     &ug ___
                &ug ___   &ug ___     &ug ___     &ug ___      &ug ___     &ug ___                                                                                &ug ___     &ug ___     &ug ___     &ug ___     &ug ___     &ug ___
                &ug ___   &ug ___     &ug ___     &ug ___      &ug ___     &ug ___                                                                                &ug GREEN   &ug BLUE    &ug BLUE    &ug BLUE    &ug GREEN   &ug ___
                &ug ___   &ug BLUE    &ug BLUE    &ug BLUE     &ug BLUE    &ug ___                                                                                &ug GREEN   &ug BLUE    &ug BLUE    &ug BLUE    &ug GREEN   &ug ___
                &ug ___   &ug ___     &ug ___     &ug ___      &ug ___     &ug ___     &ug ___     &ug ___     &ug ___      &ug ___     &ug ___     &ug ___       &ug TEAL    &ug BLUE    &ug BLUE    &ug BLUE    &ug TEAL    &ug ___
                &ug ___   &ug ___     &ug ___     &ug ___      &ug ___                 &ug ___     &ug ___     &ug ___      &ug RED     &ug GREEN   &ug BLUE                  &ug ___     &ug ___     &ug ___     &ug ___     &ug ___
            >;

            layer-id = <UK_Num>;
        };

        uk_Symbols {
            bindings = <
                &ug BLUE  &ug ___     &ug ___     &ug ___      &ug ___                                                                                                        &ug ___     &ug ___     &ug ___     &ug ___     &ug ___
                &ug ___   &ug ___     &ug ___     &ug ___      &ug ___     &ug ___                                                                                &ug ___     &ug ___     &ug ___     &ug ___     &ug ___     &ug ___
                &ug ___   &ug ___     &ug ___     &ug ___      &ug ___     &ug ___                                                                                &ug GREEN   &ug GREEN   &ug GREEN   &ug GREEN   &ug GREEN   &ug ___
                &ug ___   &ug BLUE    &ug BLUE    &ug BLUE     &ug BLUE    &ug ___                                                                                &ug GREEN   &ug GREEN   &ug GREEN   &ug GREEN   &ug GREEN   &ug ___
                &ug ___   &ug ___     &ug ___     &ug ___      &ug ___     &ug ___     &ug ___     &ug ___     &ug ___      &ug ___     &ug ___     &ug ___       &ug GREEN   &ug GREEN   &ug GREEN   &ug GREEN   &ug GREEN    &ug ___
                &ug ___   &ug ___     &ug ___     &ug ___      &ug ___                 &ug ___     &ug ___     &ug ___      &ug PINK    &ug GREEN   &ug RED                   &ug ___     &ug ___     &ug ___     &ug ___     &ug ___
            >;

            layer-id = <UK_Symbols>;
        };

        uk_Functions {
            bindings = <
                &ug BLUE  &ug ___     &ug ___     &ug ___      &ug ___                                                                                                        &ug ___     &ug ___     &ug ___     &ug ___     &ug ___
                &ug ___   &ug ___     &ug ___     &ug ___      &ug ___     &ug ___                                                                                &ug ___     &ug ___     &ug ___     &ug ___     &ug ___     &ug ___
                &ug ___   &ug ___     &ug ___     &ug ___      &ug ___     &ug ___                                                                                &ug ___     &ug BLUE    &ug BLUE    &ug BLUE    &ug TEAL    &ug ___
                &ug ___   &ug BLUE    &ug BLUE    &ug BLUE     &ug BLUE    &ug ___                                                                                &ug ___     &ug BLUE    &ug BLUE    &ug BLUE    &ug TEAL    &ug ___
                &ug ___   &ug ___     &ug ___     &ug ___      &ug ___     &ug ___     &ug ___     &ug ___     &ug ___      &ug ___     &ug ___     &ug ___       &ug ___     &ug BLUE    &ug BLUE    &ug BLUE    &ug TEAL    &ug ___
                &ug ___   &ug ___     &ug ___     &ug ___      &ug ___                 &ug ___     &ug ___     &ug ___      &ug PINK    &ug GREEN   &ug RED                   &ug ___     &ug ___     &ug ___     &ug ___     &ug ___
            >;

            layer-id = <UK_Functions>;
        };

        us_DEFAULT {
            bindings = <
                &ug BLUE  &ug ___     &ug GREEN   &ug PINK    &ug BLUE                                                                                                     &ug PINK    &ug TEAL    &ug BLUE    &ug ___     &ug ___
                &ug ___   &ug ___     &ug RED     &ug ___     &ug ___   &ug ___                                                                                &ug ___     &ug ___     &ug ___     &ug ___     &ug ___     &ug ___
                &ug ___   &ug RED     &ug RED     &ug RED     &ug RED   &ug RED                                                                                &ug RED     &ug RED     &ug RED     &ug RED     &ug RED     &ug ___
                &ug ___   &ug RED     &ug RED     &ug RED     &ug RED   &ug RED                                                                                &ug RED     &ug RED     &ug RED     &ug RED     &ug RED     &ug ___
                &ug ___   &ug RED     &ug RED     &ug RED     &ug RED   &ug RED       &ug ___     &ug ___     &ug ___      &ug ___     &ug ___     &ug ___     &ug RED     &ug RED     &ug RED     &ug RED     &ug RED     &ug ___
                &ug GOLD  &ug ___     &ug ___     &ug ___     &ug ___                 &ug WHITE   &ug YELLOW  &ug PINK     &ug PINK    &ug GREEN   &ug RED                 &ug ___     &ug ___     &ug ___     &ug ___     &ug GOLD
            >;

            layer-id = <US_DEFAULT>;
        };

        us_Nav {
            bindings = <
                &ug BLUE  &ug ___     &ug ___     &ug ___     &ug ___                                                                                                       &ug ___     &ug ___     &ug ___     &ug ___     &ug ___
                &ug ___   &ug ___     &ug ___     &ug ___     &ug ___     &ug ___                                                                                 &ug ___   &ug ___     &ug ___     &ug ___     &ug ___     &ug ___
                &ug ___   &ug GREEN   &ug PURPLE  &ug BLUE    &ug PURPLE  &ug GREEN                                                                               &ug ___   &ug ___     &ug ___     &ug ___     &ug ___     &ug ___
                &ug ___   &ug GREEN   &ug BLUE    &ug BLUE    &ug BLUE    &ug GREEN                                                                               &ug ___   &ug BLUE    &ug BLUE    &ug BLUE    &ug BLUE    &ug ___
                &ug ___   &ug TEAL    &ug TEAL    &ug TEAL    &ug TEAL    &ug TEAL    &ug ___     &ug ___     &ug ___      &ug ___     &ug ___     &ug ___        &ug ___   &ug ___     &ug ___     &ug ___     &ug ___     &ug ___
                &ug ___   &ug ___     &ug ___     &ug ___     &ug ___                 &ug WHITE   &ug YELLOW   &ug PINK    &ug ___     &ug ___   &ug ___                    &ug ___     &ug ___     &ug ___     &ug ___     &ug ___
            >;

            layer-id = <US_Nav>;
        };

        us_Coding {
            bindings = <
                &ug BLUE  &ug ___     &ug ___     &ug ___      &ug ___                                                                                                        &ug ___     &ug ___     &ug ___     &ug ___     &ug ___
                &ug ___   &ug ___     &ug ___     &ug ___      &ug ___     &ug ___                                                                                &ug ___     &ug ___     &ug ___     &ug ___     &ug ___     &ug ___
                &ug ___   &ug TEAL    &ug TEAL    &ug TEAL     &ug TEAL    &ug TEAL                                                                               &ug ___     &ug ___     &ug ___     &ug ___     &ug ___     &ug ___
                &ug ___   &ug GREEN   &ug BLUE    &ug PURPLE   &ug YELLOW  &ug RED                                                                                &ug ___     &ug BLUE    &ug BLUE    &ug BLUE    &ug BLUE    &ug ___
                &ug ___   &ug GREEN   &ug BLUE    &ug PURPLE   &ug YELLOW  &ug RED     &ug ___     &ug ___     &ug ___      &ug ___     &ug ___     &ug ___       &ug ___     &ug ___     &ug ___     &ug ___     &ug ___     &ug ___
                &ug ___   &ug ___     &ug ___     &ug ___      &ug ___                 &ug WHITE   &ug YELLOW  &ug PINK     &ug ___     &ug ___    &ug ___                    &ug ___     &ug ___     &ug ___     &ug ___     &ug ___
            >;

            layer-id = <US_Coding>;
        };

        us_Macros {
            bindings = <
                &ug BLUE  &ug ___     &ug ___     &ug ___      &ug ___                                                                                                        &ug ___     &ug ___     &ug ___     &ug ___     &ug ___
                &ug ___   &ug ___     &ug ___     &ug ___      &ug ___     &ug ___                                                                                &ug ___     &ug ___     &ug ___     &ug ___     &ug ___     &ug ___
                &ug ___   &ug GREEN   &ug ___     &ug ___      &ug ___     &ug ___                                                                                &ug ___     &ug ___     &ug ___     &ug ___     &ug ___     &ug ___
                &ug ___   &ug GREEN   &ug BLUE    &ug TEAL     &ug BLUE    &ug ___                                                                                &ug ___     &ug BLUE    &ug BLUE    &ug BLUE    &ug BLUE    &ug ___
                &ug ___   &ug PURPLE  &ug PURPLE  &ug PURPLE   &ug PURPLE  &ug ___     &ug ___     &ug ___     &ug ___      &ug ___     &ug ___     &ug ___       &ug ___     &ug ___     &ug ___     &ug ___     &ug ___     &ug ___
                &ug ___   &ug ___     &ug ___     &ug ___      &ug ___                 &ug WHITE   &ug YELLOW  &ug PINK     &ug ___     &ug ___     &ug ___                   &ug ___     &ug ___     &ug ___     &ug ___     &ug ___
            >;

            layer-id = <US_Macros>;
        };

        us_Num {
            bindings = <
                &ug BLUE  &ug ___     &ug ___     &ug ___      &ug ___                                                                                                        &ug ___     &ug ___     &ug ___     &ug ___     &ug ___
                &ug ___   &ug ___     &ug ___     &ug ___      &ug ___     &ug ___                                                                                &ug ___     &ug ___     &ug ___     &ug ___     &ug ___     &ug ___
                &ug ___   &ug ___     &ug ___     &ug ___      &ug ___     &ug ___                                                                                &ug GREEN   &ug BLUE    &ug BLUE    &ug BLUE    &ug GREEN   &ug ___
                &ug ___   &ug BLUE    &ug BLUE    &ug BLUE     &ug BLUE    &ug ___                                                                                &ug GREEN   &ug BLUE    &ug BLUE    &ug BLUE    &ug GREEN   &ug ___
                &ug ___   &ug ___     &ug ___     &ug ___      &ug ___     &ug ___     &ug ___     &ug ___     &ug ___      &ug ___     &ug ___     &ug ___       &ug TEAL    &ug BLUE    &ug BLUE    &ug BLUE    &ug TEAL    &ug ___
                &ug ___   &ug ___     &ug ___     &ug ___      &ug ___                 &ug ___     &ug ___     &ug ___      &ug RED     &ug GREEN   &ug BLUE                  &ug ___     &ug ___     &ug ___     &ug ___     &ug ___
            >;

            layer-id = <US_Num>;
        };

        us_Symbols {
            bindings = <
                &ug BLUE  &ug ___     &ug ___     &ug ___      &ug ___                                                                                                        &ug ___     &ug ___     &ug ___     &ug ___     &ug ___
                &ug ___   &ug ___     &ug ___     &ug ___      &ug ___     &ug ___                                                                                &ug ___     &ug ___     &ug ___     &ug ___     &ug ___     &ug ___
                &ug ___   &ug ___     &ug ___     &ug ___      &ug ___     &ug ___                                                                                &ug GREEN   &ug GREEN   &ug GREEN   &ug GREEN   &ug GREEN   &ug ___
                &ug ___   &ug BLUE    &ug BLUE    &ug BLUE     &ug BLUE    &ug ___                                                                                &ug GREEN   &ug GREEN   &ug GREEN   &ug GREEN   &ug GREEN   &ug ___
                &ug ___   &ug ___     &ug ___     &ug ___      &ug ___     &ug ___     &ug ___     &ug ___     &ug ___      &ug ___     &ug ___     &ug ___       &ug GREEN   &ug GREEN   &ug GREEN   &ug GREEN   &ug GREEN    &ug ___
                &ug ___   &ug ___     &ug ___     &ug ___      &ug ___                 &ug ___     &ug ___     &ug ___      &ug PINK    &ug GREEN   &ug RED                   &ug ___     &ug ___     &ug ___     &ug ___     &ug ___
            >;

            layer-id = <US_Symbols>;
        };

        us_Functions {
            bindings = <
                &ug BLUE  &ug ___     &ug ___     &ug ___      &ug ___                                                                                                        &ug ___     &ug ___     &ug ___     &ug ___     &ug ___
                &ug ___   &ug ___     &ug ___     &ug ___      &ug ___     &ug ___                                                                                &ug ___     &ug ___     &ug ___     &ug ___     &ug ___     &ug ___
                &ug ___   &ug ___     &ug ___     &ug ___      &ug ___     &ug ___                                                                                &ug ___     &ug BLUE    &ug BLUE    &ug BLUE    &ug TEAL    &ug ___
                &ug ___   &ug BLUE    &ug BLUE    &ug BLUE     &ug BLUE    &ug ___                                                                                &ug ___     &ug BLUE    &ug BLUE    &ug BLUE    &ug TEAL    &ug ___
                &ug ___   &ug ___     &ug ___     &ug ___      &ug ___     &ug ___     &ug ___     &ug ___     &ug ___      &ug ___     &ug ___     &ug ___       &ug ___     &ug BLUE    &ug BLUE    &ug BLUE    &ug TEAL    &ug ___
                &ug ___   &ug ___     &ug ___     &ug ___      &ug ___                 &ug ___     &ug ___     &ug ___      &ug PINK    &ug GREEN   &ug RED                   &ug ___     &ug ___     &ug ___     &ug ___     &ug ___
            >;

            layer-id = <US_Functions>;
        };
    };
};
